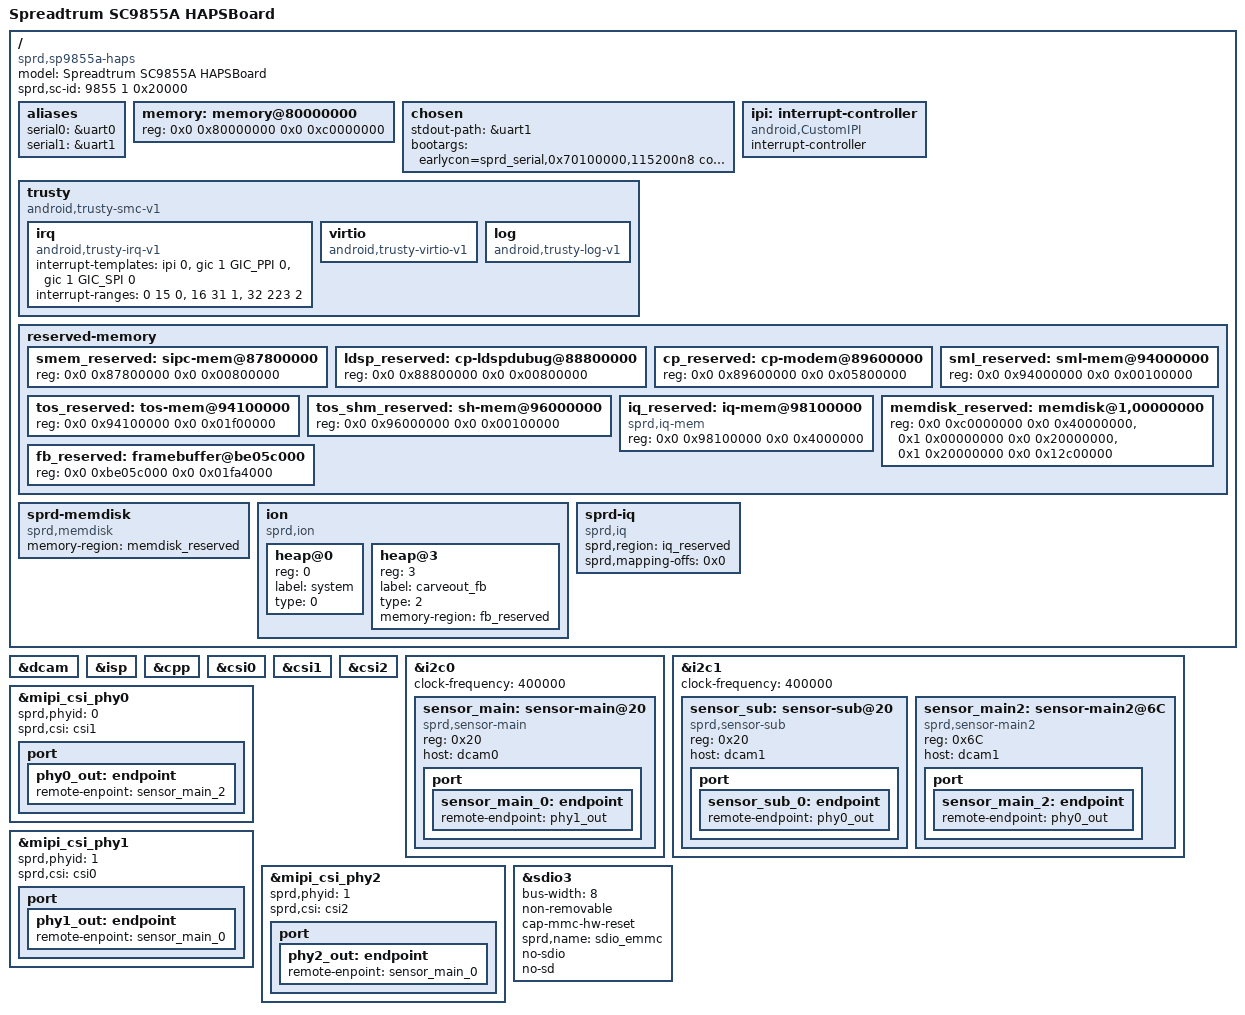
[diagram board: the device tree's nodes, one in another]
/*
 * Spreadtrum sharkl3 Haps board DTS file
 *
 * Copyright (C) 2017, Spreadtrum Communications Inc.
 *
 * This file is licensed under a dual GPLv2 or X11 license.
 */
/dts-v1/;

#include "sc9855ahaps.dtsi"
#include "sp9855ahaps-common.dtsi"

/ {
	model = "Spreadtrum SC9855A HAPSBoard";

	compatible = "sprd,sp9855a-haps", "sprd,sc9855a";

	sprd,sc-id = <9855 1 0x20000>;

	aliases {
		serial0 = &uart0;
		serial1 = &uart1;
	};

	memory: memory@80000000 {
		device_type = "memory";
		reg = <0x0 0x80000000 0x0 0xc0000000>;
	};

	chosen {
		stdout-path = &uart1;
		bootargs = "earlycon=sprd_serial,0x70100000,115200n8 console=ttyS1,115200n8 loglevel=8 init=/init root=/dev/ram0 rw androidboot.hardware=sp9855a_haps androidboot.selinux=permissive swiotlb=64k";
	};

	ipi: interrupt-controller {
		compatible = "android,CustomIPI";
		#interrupt-cells = <1>;
		interrupt-controller;
	};

	trusty {
		compatible = "android,trusty-smc-v1";

		irq {
			compatible = "android,trusty-irq-v1";
			interrupt-templates = <&ipi 0>,
						<&gic 1 GIC_PPI 0>,
						<&gic 1 GIC_SPI 0>;
			interrupt-ranges = < 0  15 0>,
						<16  31 1>,
						<32 223 2>;
		};

		virtio {
			compatible = "android,trusty-virtio-v1";
		};

		log {
			compatible = "android,trusty-log-v1";
		};
	};

	reserved-memory {
		#address-cells = <2>;
		#size-cells = <2>;
		ranges;

		smem_reserved: sipc-mem@87800000{
			reg = <0x0 0x87800000 0x0 0x00800000>;
		};

		ldsp_reserved: cp-ldspdubug@88800000 {
			reg = <0x0 0x88800000 0x0 0x00800000>;
		};

		cp_reserved: cp-modem@89600000 {
			reg = <0x0 0x89600000 0x0 0x05800000>;
		};
		/* must be 64M aligned */
		sml_reserved: sml-mem@94000000{
			reg = <0x0 0x94000000 0x0 0x00100000>;
		};

		tos_reserved: tos-mem@94100000{
			reg = <0x0 0x94100000 0x0 0x01f00000>;
		};

		tos_shm_reserved: sh-mem@96000000{
			reg = <0x0 0x96000000 0x0 0x00100000>;
		};
		/* Only used for iq, will be removed in normal mode by uboot */
		iq_reserved: iq-mem@98100000{
			compatible = "sprd,iq-mem";
			reg = <0x0 0x98100000 0x0 0x4000000>;
		};

		memdisk_reserved: memdisk@1,00000000{
			reg = <0x0 0xc0000000 0x0 0x40000000>,	/* system */
				<0x1 0x00000000 0x0 0x20000000>, /* userdata */
				<0x1 0x20000000 0x0 0x12c00000>; /* vendor */
		};

		fb_reserved: framebuffer@be05c000{
			reg = <0x0 0xbe05c000 0x0 0x01fa4000>;
		};
	};

	sprd-memdisk {
		compatible = "sprd,memdisk";
		memory-region = <&memdisk_reserved>;
	};

	ion {
		compatible = "sprd,ion";
		#address-cells = <1>;
		#size-cells = <0>;

		heap@0 {
			reg = <0>;
			label = "system";
			type = <0>;
		};

		heap@3 {
			reg = <3>;
			label = "carveout_fb";
			type = <2>;
			memory-region = <&fb_reserved>;
		};
	};

	sprd-iq {
		compatible = "sprd,iq";
		sprd,region = <&iq_reserved>;
		sprd,mapping-offs = <0x0>;
	};
};

&dcam {
	status = "okay";
};

&isp {
	status = "okay";
};

&cpp {
	status = "okay";
};

&csi0 {
	status = "okay";
};

&csi1 {
	status = "okay";
};

&csi2 {
	status = "okay";
};

&i2c0 {
	status = "okay";
	clock-frequency = <400000>;

	sensor_main: sensor-main@20 {
		compatible = "sprd,sensor-main";
		reg = <0x20>;
		host = "dcam0";
		port {
			sensor_main_0: endpoint {
				remote-endpoint = <&phy1_out>;
			};
		};
	};
};

&i2c1 {
	status = "okay";
	clock-frequency = <400000>;

	sensor_sub: sensor-sub@20 {
		compatible = "sprd,sensor-sub";
		reg = <0x20>;
		host = "dcam1";
		port {
			sensor_sub_0: endpoint {
				remote-endpoint = <&phy0_out>;
			};
		};
	};

	sensor_main2: sensor-main2@6C {
		compatible = "sprd,sensor-main2";
		reg = <0x6C>;
		host = "dcam1";
		port {
			sensor_main_2: endpoint {
				remote-endpoint = <&phy0_out>;
			};
		};
	};
};

&mipi_csi_phy0 {
	status = "okay";
	sprd,phyid = <0>;
	sprd,csi = <&csi1>;
	port {
		phy0_out: endpoint {
			remote-enpoint = <&sensor_main_2>;
		};
	};
};

&mipi_csi_phy1 {
	status = "okay";
	sprd,phyid = <1>;
	sprd,csi = <&csi0>;
	port {
		phy1_out: endpoint {
			remote-enpoint = <&sensor_main_0>;
		};
	};
};

&mipi_csi_phy2 {
	status = "okay";
	sprd,phyid = <1>;
	sprd,csi = <&csi2>;
	port {
		phy2_out: endpoint {
			remote-enpoint = <&sensor_main_0>;
		};
	};
};

&sdio3 {
	bus-width = <8>;
	non-removable;
	cap-mmc-hw-reset;
	sprd,name = "sdio_emmc";
	no-sdio;
	no-sd;
	status = "okay";
};

